# STM32H733ZGT6 register map
File version: 1.0
Registers are 32-bit, access not given, reset 0x0 unless marked. A register's access mark holds for its fields unless they carry their own. Offsets are from the block's base; [hi:lo] are bit positions; {n}, {i} and the like mark numbered series.

## USB1_OTG_HS
Base 0x40040000
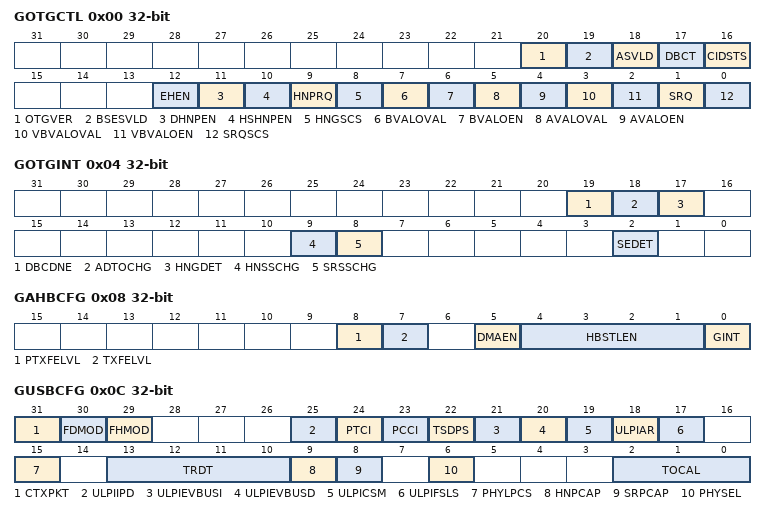
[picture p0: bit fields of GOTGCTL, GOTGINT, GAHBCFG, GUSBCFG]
0x00 GOTGCTL
  [20] OTGVER, [19] BSESVLD, [18] ASVLD, [17] DBCT, [16] CIDSTS, [12] EHEN, [11] DHNPEN, [10] HSHNPEN, [9] HNPRQ, [8] HNGSCS, [7] BVALOVAL, [6] BVALOEN, [5] AVALOVAL, [4] AVALOEN, [3] VBVALOVAL, [2] VBVALOEN, [1] SRQ, [0] SRQSCS
0x04 GOTGINT
  [19] DBCDNE, [18] ADTOCHG, [17] HNGDET, [9] HNSSCHG, [8] SRSSCHG, [2] SEDET
0x08 GAHBCFG
  [8] PTXFELVL, [7] TXFELVL, [5] DMAEN, [4:1] HBSTLEN, [0] GINT
0x0C GUSBCFG
  [31] CTXPKT, [30] FDMOD, [29] FHMOD, [25] ULPIIPD, [24] PTCI, [23] PCCI, [22] TSDPS, [21] ULPIEVBUSI, [20] ULPIEVBUSD, [19] ULPICSM, [18] ULPIAR, [17] ULPIFSLS, [15] PHYLPCS, [13:10] TRDT, [9] HNPCAP, [8] SRPCAP, [6] PHYSEL, [2:0] TOCAL
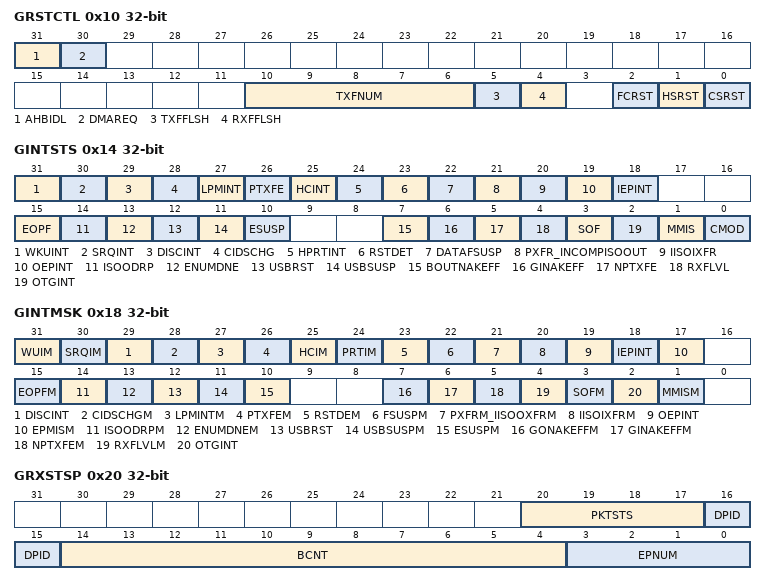
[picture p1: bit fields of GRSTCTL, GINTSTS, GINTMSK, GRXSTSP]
0x10 GRSTCTL
  [31] AHBIDL, [30] DMAREQ, [10:6] TXFNUM, [5] TXFFLSH, [4] RXFFLSH, [2] FCRST, [1] HSRST, [0] CSRST
0x14 GINTSTS
  [31] WKUINT, [30] SRQINT, [29] DISCINT, [28] CIDSCHG, [27] LPMINT, [26] PTXFE, [25] HCINT, [24] HPRTINT, [23] RSTDET, [22] DATAFSUSP, [21] PXFR_INCOMPISOOUT, [20] IISOIXFR, [19] OEPINT, [18] IEPINT, [15] EOPF, [14] ISOODRP, [13] ENUMDNE, [12] USBRST, [11] USBSUSP, [10] ESUSP, [7] BOUTNAKEFF, [6] GINAKEFF, [5] NPTXFE, [4] RXFLVL, [3] SOF, [2] OTGINT, [1] MMIS, [0] CMOD
0x18 GINTMSK
  [31] WUIM, [30] SRQIM, [29] DISCINT, [28] CIDSCHGM, [27] LPMINTM, [26] PTXFEM, [25] HCIM, [24] PRTIM, [23] RSTDEM, [22] FSUSPM, [21] PXFRM_IISOOXFRM, [20] IISOIXFRM, [19] OEPINT, [18] IEPINT, [17] EPMISM, [15] EOPFM, [14] ISOODRPM, [13] ENUMDNEM, [12] USBRST, [11] USBSUSPM, [10] ESUSPM, [7] GONAKEFFM, [6] GINAKEFFM, [5] NPTXFEM, [4] RXFLVLM, [3] SOFM, [2] OTGINT, [1] MMISM
0x1C GRXSTSR
0x20 GRXSTSP
  [20:17] PKTSTS, [16:15] DPID, [14:4] BCNT, [3:0] EPNUM
0x24 GRXFSIZ
  [15:0] RXFD
0x28 DIEPTXF0_HNPTXFSIZ
0x2C HNPTXSTS
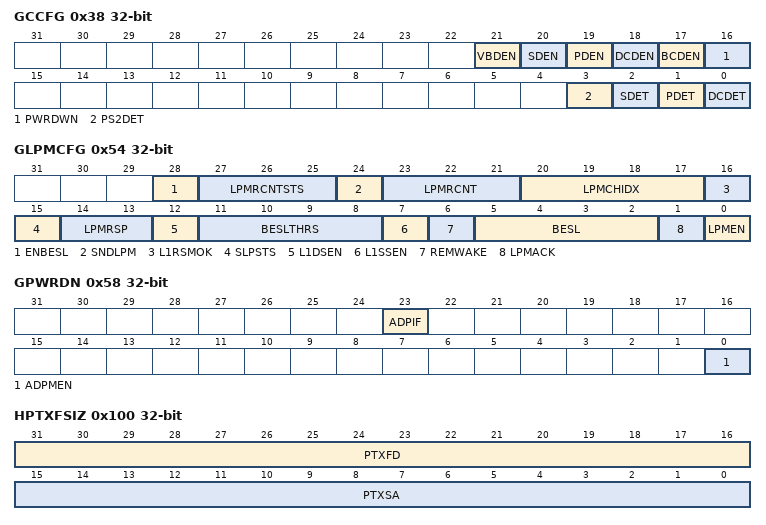
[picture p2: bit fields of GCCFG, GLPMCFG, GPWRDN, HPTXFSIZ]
0x38 GCCFG
  [21] VBDEN, [20] SDEN, [19] PDEN, [18] DCDEN, [17] BCDEN, [16] PWRDWN, [3] PS2DET, [2] SDET, [1] PDET, [0] DCDET
0x3C CID
  [31:0] PRODUCT_ID
0x40 GSNPSID
{0x40+4i} GHWCFG{i} (i=1..3)
0x54 GLPMCFG
  [28] ENBESL, [27:25] LPMRCNTSTS, [24] SNDLPM, [23:21] LPMRCNT, [20:17] LPMCHIDX, [16] L1RSMOK, [15] SLPSTS, [14:13] LPMRSP, [12] L1DSEN, [11:8] BESLTHRS, [7] L1SSEN, [6] REMWAKE, [5:2] BESL, [1] LPMACK, [0] LPMEN
0x58 GPWRDN
  [23] ADPIF, [0] ADPMEN
0x5C GDFIFOCFG
0x60 GADPCTL
0x100 HPTXFSIZ
  [31:16] PTXFD, [15:0] PTXSA
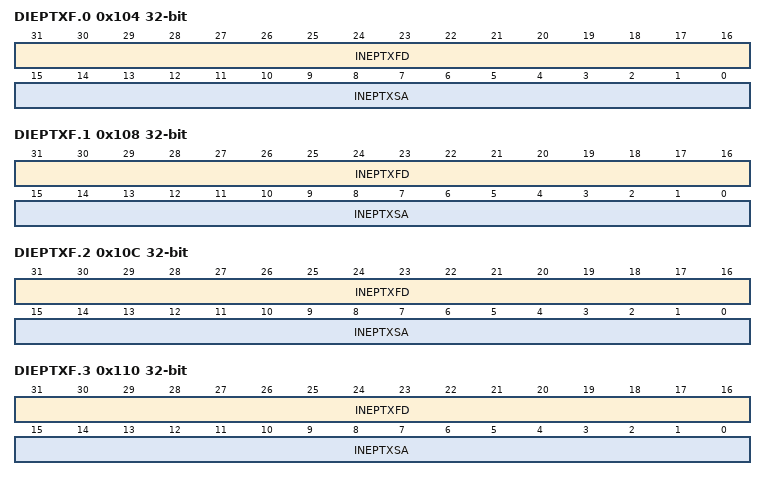
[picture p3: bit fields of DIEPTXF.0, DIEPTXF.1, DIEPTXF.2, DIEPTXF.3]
0x104 DIEPTXF.0
  [31:16] INEPTXFD, [15:0] INEPTXSA
0x108 DIEPTXF.1
  [31:16] INEPTXFD, [15:0] INEPTXSA
0x10C DIEPTXF.2
  [31:16] INEPTXFD, [15:0] INEPTXSA
0x110 DIEPTXF.3
  [31:16] INEPTXFD, [15:0] INEPTXSA
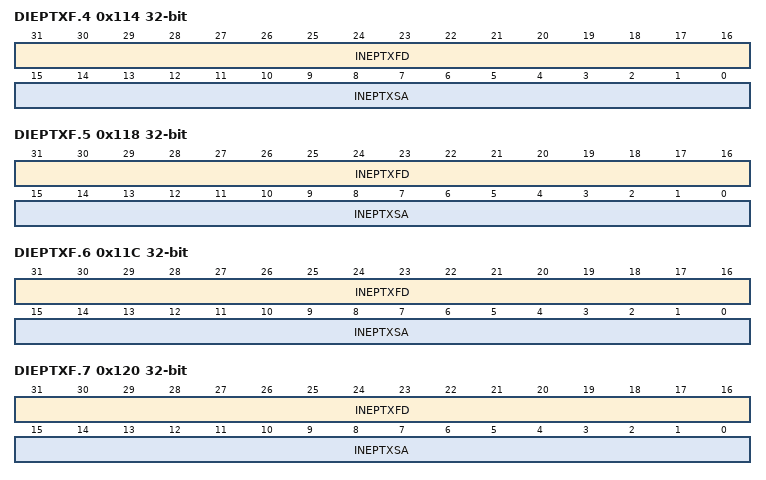
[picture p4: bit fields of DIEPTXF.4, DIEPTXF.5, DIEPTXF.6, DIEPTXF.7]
0x114 DIEPTXF.4
  [31:16] INEPTXFD, [15:0] INEPTXSA
0x118 DIEPTXF.5
  [31:16] INEPTXFD, [15:0] INEPTXSA
0x11C DIEPTXF.6
  [31:16] INEPTXFD, [15:0] INEPTXSA
0x120 DIEPTXF.7
  [31:16] INEPTXFD, [15:0] INEPTXSA
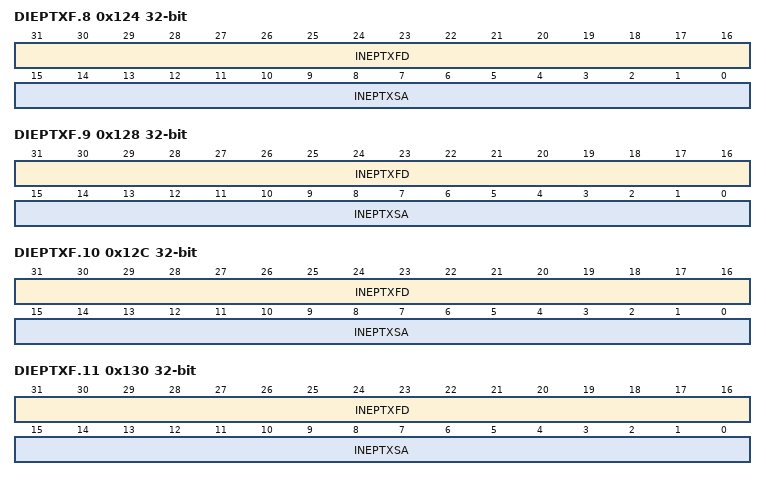
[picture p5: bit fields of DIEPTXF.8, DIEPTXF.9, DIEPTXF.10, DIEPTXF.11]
0x124 DIEPTXF.8
  [31:16] INEPTXFD, [15:0] INEPTXSA
0x128 DIEPTXF.9
  [31:16] INEPTXFD, [15:0] INEPTXSA
0x12C DIEPTXF.10
  [31:16] INEPTXFD, [15:0] INEPTXSA
0x130 DIEPTXF.11
  [31:16] INEPTXFD, [15:0] INEPTXSA
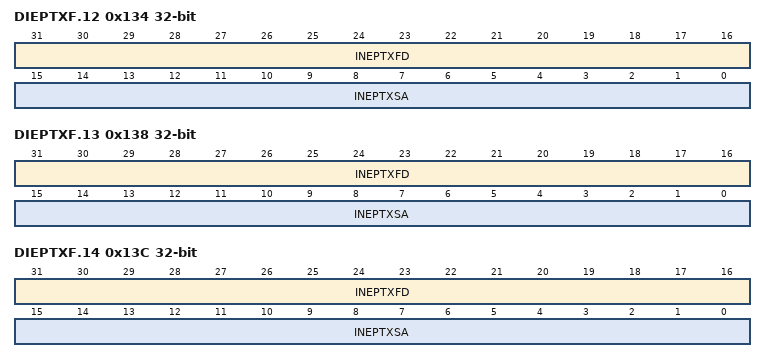
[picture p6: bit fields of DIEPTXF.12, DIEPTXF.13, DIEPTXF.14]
0x134 DIEPTXF.12
  [31:16] INEPTXFD, [15:0] INEPTXSA
0x138 DIEPTXF.13
  [31:16] INEPTXFD, [15:0] INEPTXSA
0x13C DIEPTXF.14
  [31:16] INEPTXFD, [15:0] INEPTXSA

## DCMI
Base 0x48020000
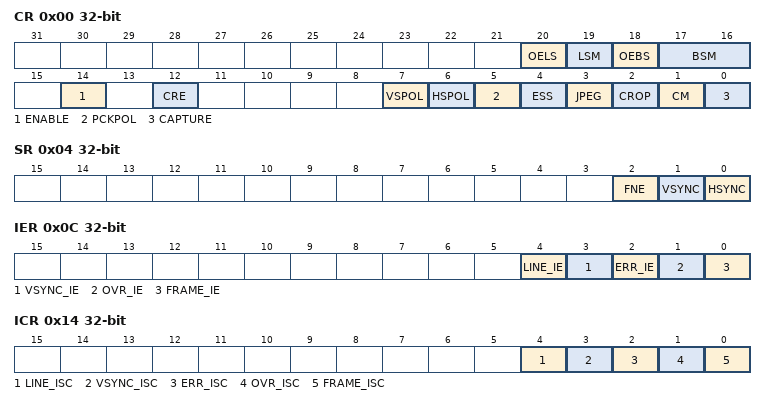
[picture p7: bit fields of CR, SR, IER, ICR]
0x00 CR
  [20] OELS, [19] LSM, [18] OEBS, [17:16] BSM, [14] ENABLE, [12] CRE, [7] VSPOL, [6] HSPOL, [5] PCKPOL, [4] ESS, [3] JPEG, [2] CROP, [1] CM, [0] CAPTURE
0x04 SR
  [2] FNE, [1] VSYNC, [0] HSYNC
0x08 RISR
0x0C IER
  [4] LINE_IE, [3] VSYNC_IE, [2] ERR_IE, [1] OVR_IE, [0] FRAME_IE
0x10 MISR
0x14 ICR
  [4] LINE_ISC, [3] VSYNC_ISC, [2] ERR_ISC, [1] OVR_ISC, [0] FRAME_ISC
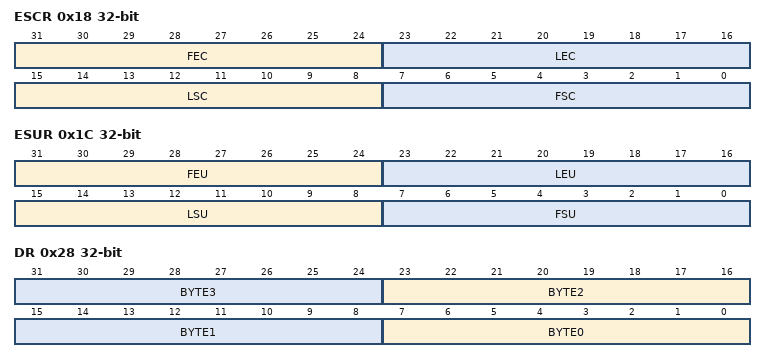
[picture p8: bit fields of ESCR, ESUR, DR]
0x18 ESCR
  [31:24] FEC, [23:16] LEC, [15:8] LSC, [7:0] FSC
0x1C ESUR
  [31:24] FEU, [23:16] LEU, [15:8] LSU, [7:0] FSU
0x20 CWSTRTR
0x24 CWSIZER
0x28 DR
  [8n+7:8n] BYTE{n} (n=0..3)

## PSSI
Base 0x48020400
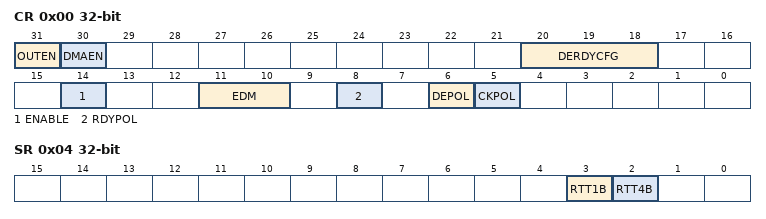
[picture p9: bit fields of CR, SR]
0x00 CR
  [31] OUTEN, [30] DMAEN, [20:18] DERDYCFG, [14] ENABLE, [11:10] EDM, [8] RDYPOL, [6] DEPOL, [5] CKPOL
0x04 SR
  [3] RTT1B, [2] RTT4B
0x08 RIS
  [1] OVR_RIS
0x0C IER
  [1] OVR_IE
0x10 MIS
  [1] OVR_MIS
0x14 ICR
  [1] OVR_ISC
0x28 DR
0x3F0 HWCFGR
0x3F4 VERR
0x3F8 IPIDR
0x3FC SIDR
